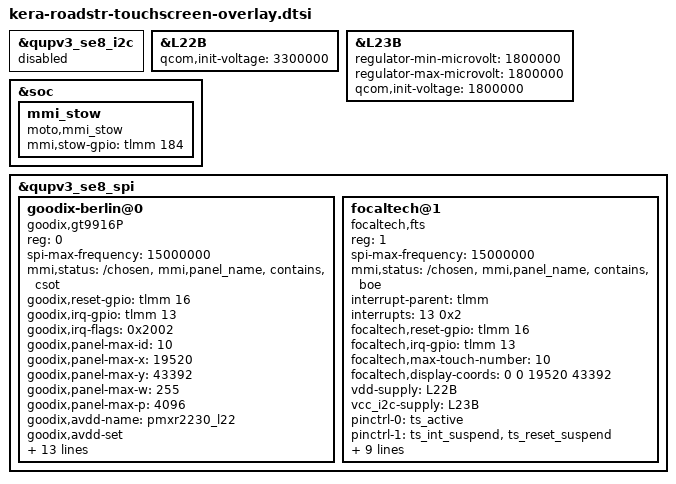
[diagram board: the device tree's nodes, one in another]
/*
 * Copyright (c) 2024, The Linux Foundation. All rights reserved.
 *
 * This program is free software; you can redistribute it and/or modify
 * it under the terms of the GNU General Public License version 2 and
 * only version 2 as published by the Free Software Foundation.
 *
 * This program is distributed in the hope that it will be useful,
 * but WITHOUT ANY WARRANTY; without even the implied warranty of
 * MERCHANTABILITY or FITNESS FOR A PARTICULAR PURPOSE.  See the
 * GNU General Public License for more details.
 */
#include <dt-bindings/clock/qcom,rpmh.h>
#include <dt-bindings/regulator/qcom,rpmh-regulator-levels.h>

&qupv3_se8_i2c {
	status = "disabled";
};

&L22B {
	qcom,init-voltage = <3300000>;
};

&L23B {
	regulator-min-microvolt = <1800000>;
	regulator-max-microvolt = <1800000>;
	qcom,init-voltage = <1800000>;
};

&soc {
	mmi_stow {
		compatible = "moto,mmi_stow";
		mmi,stow-gpio = <&tlmm 184 0x0>;
	};
};

&qupv3_se8_spi {
	#address-cells = <1>;
	#size-cells = <0>;

	status = "ok";

	goodix-berlin@0 {
		status = "ok";
		compatible = "goodix,gt9916P";
		reg = <0>;
		spi-max-frequency = <15000000>;
		mmi,status = "/chosen","mmi,panel_name","contains","csot";

		goodix,reset-gpio = <&tlmm 16 0x0>;
		goodix,irq-gpio = <&tlmm 13 0x2002>;
		goodix,irq-flags = <0x2002>; /* 1:trigger rising, 2:trigger falling;*/
		goodix,panel-max-id = <10>;
		goodix,panel-max-x = <19520>;
		goodix,panel-max-y = <43392>;
		goodix,panel-max-w = <255>;
		goodix,panel-max-p = <4096>;
		goodix,avdd-name = "pmxr2230_l22";
		goodix,avdd-set;
		goodix,iovdd-name = "pmxr2230_l23";
		pinctrl-names = "pmx_ts_active", "pmx_ts_suspend", "pmx_ts_release";
		pinctrl-0 = <&ts_active>;
		pinctrl-1 = <&ts_int_suspend &ts_reset_suspend>;
		pinctrl-2 = <&ts_release>;

		mmi,power-off-suspend;
		mmi,usb-charger-detection;
		mmi,supported_gesture_type = <0x07>;
		mmi,enable-gestures;
		goodix,gesture-wait-pm;
		mmi,resolution_boost = <16>;
		goodix,sample-ctrl;
		goodix,edge-ctrl;
		goodix,interpolation-ctrl;
//		mmi,refresh-rate-update;
//		goodix,report_rate-ctrl;
	};

	focaltech@1 {
		compatible = "focaltech,fts";
		reg = <1>;
		spi-max-frequency = <15000000>;
		mmi,status = "/chosen","mmi,panel_name","contains","boe";

		interrupt-parent = <&tlmm>;
		interrupts = <13 0x2>;
		focaltech,reset-gpio = <&tlmm 16 0x0>;
		focaltech,irq-gpio = <&tlmm 13 0x02>;
		focaltech,max-touch-number = <10>;
		focaltech,display-coords =  <0 0 19520 43392>;
		vdd-supply=<&L22B>;
		vcc_i2c-supply=<&L23B>;

		pinctrl-names = "pmx_ts_active", "pmx_ts_suspend", "pmx_ts_release";
		pinctrl-0 = <&ts_active>;
		pinctrl-1 = <&ts_int_suspend &ts_reset_suspend>;
		pinctrl-2 = <&ts_release>;

		focaltech,sample-ctrl;
		focaltech,edge-ctrl;
		focaltech,interpolation-ctrl;
		mmi,power-off-suspend;
		mmi,enable-gestures;
		mmi,supported_gesture_type = <0x07>;
		mmi,resolution_boost = <16>;
		mmi,usb-charger-detection;
	};
};
